# ATSAM3A8C register map
Vendor: Atmel; Series: SAM3A; File version: 0
CPU: CM3 r2p0, selectable endian, MPU, no FPU, 4 interrupt priority bits
Registers are 32-bit, read-write, reset 0x0 unless marked. A register's access mark holds for its fields unless they carry their own. Offsets are from the block's base; [hi:lo] are bit positions; {n}, {i} and the like mark numbered series.

## PMC — Power Management Controller
Base 0x400E0600
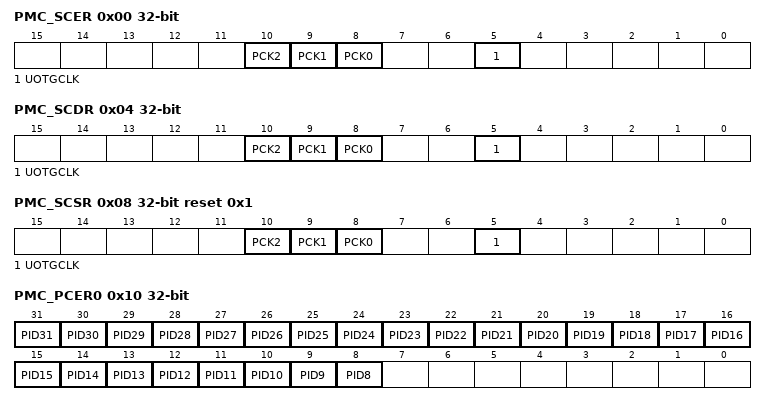
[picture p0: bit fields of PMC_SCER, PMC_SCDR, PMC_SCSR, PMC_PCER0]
0x00 PMC_SCER wo reset not defined — System Clock Enable Register
  [10] PCK2 — Programmable Clock 2 Output Enable
  [9] PCK1 — Programmable Clock 1 Output Enable
  [8] PCK0 — Programmable Clock 0 Output Enable
  [5] UOTGCLK — Enable USB OTG Clock (48 MHz, USB_48M) for UTMI
0x04 PMC_SCDR wo reset not defined — System Clock Disable Register
  [10] PCK2 — Programmable Clock 2 Output Disable
  [9] PCK1 — Programmable Clock 1 Output Disable
  [8] PCK0 — Programmable Clock 0 Output Disable
  [5] UOTGCLK — Disable USB OTG Clock (48 MHz, USB_48M) for UTMI
0x08 PMC_SCSR ro reset 0x1 — System Clock Status Register
  [10] PCK2 — Programmable Clock 2 Output Status
  [9] PCK1 — Programmable Clock 1 Output Status
  [8] PCK0 — Programmable Clock 0 Output Status
  [5] UOTGCLK — USB OTG Clock (48 MHz, USB_48M) Clock Status
0x10 PMC_PCER0 wo reset not defined — Peripheral Clock Enable Register 0
  [n] PID{n} (n=8..31) — Peripheral Clock {n} Enable
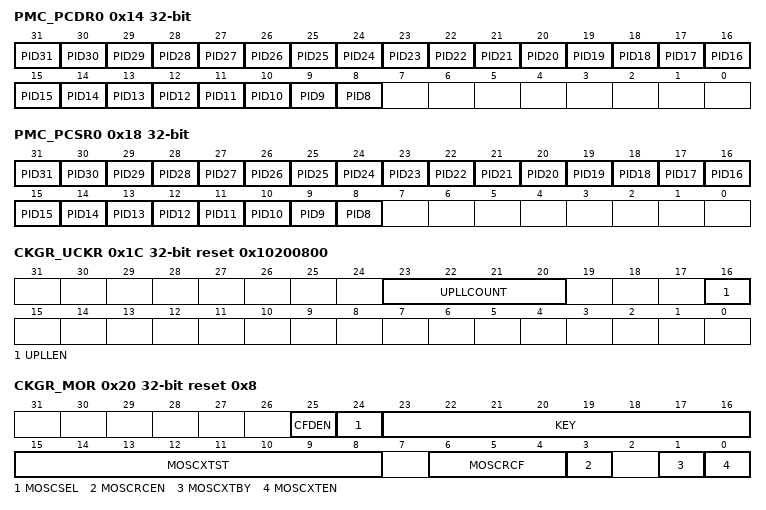
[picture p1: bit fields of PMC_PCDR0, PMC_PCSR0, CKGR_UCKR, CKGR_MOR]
0x14 PMC_PCDR0 wo reset not defined — Peripheral Clock Disable Register 0
  [n] PID{n} (n=8..31) — Peripheral Clock {n} Disable
0x18 PMC_PCSR0 ro — Peripheral Clock Status Register 0
  [n] PID{n} (n=8..31) — Peripheral Clock {n} Status
0x1C CKGR_UCKR reset 0x10200800 — UTMI Clock Register
  [23:20] UPLLCOUNT — UTMI PLL Start-up Time
  [16] UPLLEN — UTMI PLL Enable
0x20 CKGR_MOR reset 0x8 — Main Oscillator Register
  [25] CFDEN — Clock Failure Detector Enable
  [24] MOSCSEL — Main Oscillator Selection
  [23:16] KEY — Write Access Password
    55=PASSWD (Writing any other value in this field aborts the write operation.Always reads as 0.)
  [15:8] MOSCXTST — Main Crystal Oscillator Start-up Time
  [6:4] MOSCRCF — Main On-Chip RC Oscillator Frequency Selection
    0=4_MHz (The Fast RC Oscillator Frequency is at 4 MHz (default)); 1=8_MHz (The Fast RC Oscillator Frequency is at 8 MHz); 2=12_MHz (The Fast RC Oscillator Frequency is at 12 MHz)
  [3] MOSCRCEN — Main On-Chip RC Oscillator Enable
  [1] MOSCXTBY — Main Crystal Oscillator Bypass
  [0] MOSCXTEN — Main Crystal Oscillator Enable
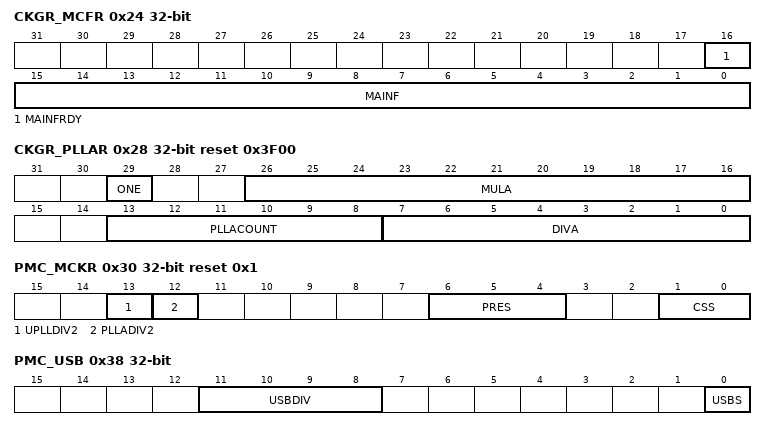
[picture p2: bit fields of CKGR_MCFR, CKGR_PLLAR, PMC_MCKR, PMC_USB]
0x24 CKGR_MCFR ro — Main Clock Frequency Register
  [16] MAINFRDY — Main Clock Ready
  [15:0] MAINF — Main Clock Frequency
0x28 CKGR_PLLAR reset 0x3F00 — PLLA Register
  [29] ONE — Must Be Set to 1
  [26:16] MULA — PLLA Multiplier
  [13:8] PLLACOUNT — PLLA Counter
  [7:0] DIVA — Divider
0x30 PMC_MCKR reset 0x1 — Master Clock Register
  [13] UPLLDIV2
  [12] PLLADIV2 — PLLA Divisor by 2
  [6:4] PRES — Processor Clock Prescaler
    0=CLK_1 (Selected clock); 1=CLK_2 (Selected clock divided by 2); 2=CLK_4 (Selected clock divided by 4); 3=CLK_8 (Selected clock divided by 8); 4=CLK_16 (Selected clock divided by 16); 5=CLK_32 (Selected clock divided by 32); 6=CLK_64 (Selected clock divided by 64); 7=CLK_3 (Selected clock divided by 3)
  [1:0] CSS — Master Clock Source Selection
    0=SLOW_CLK (Slow Clock is selected); 1=MAIN_CLK (Main Clock is selected); 2=PLLA_CLK (PLLA Clock is selected); 3=UPLL_CLK (UPLL Clock is selected)
0x38 PMC_USB — USB Clock Register
  [11:8] USBDIV — Divider for USB Clock.
  [0] USBS — USB Input Clock Selection
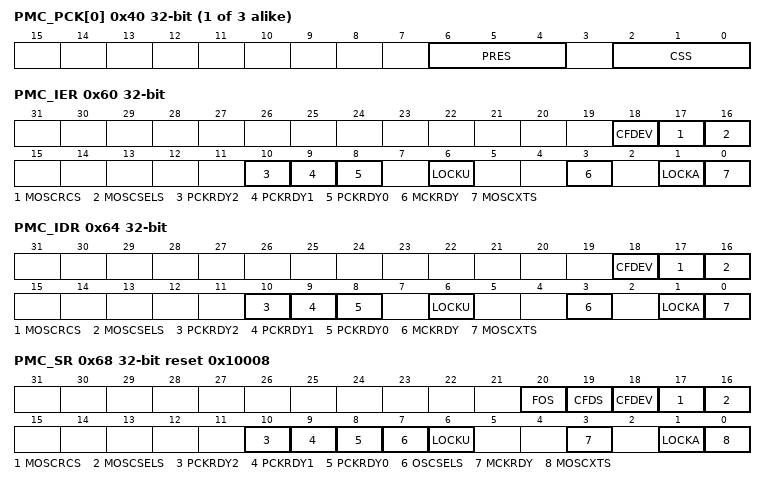
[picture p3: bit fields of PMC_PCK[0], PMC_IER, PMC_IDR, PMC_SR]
{0x40+4i} PMC_PCK[{i}] (i=0..2) reset not defined — Programmable Clock 0 Register
  [6:4] PRES — Programmable Clock Prescaler
    0=CLK_1 (Selected clock); 1=CLK_2 (Selected clock divided by 2); 2=CLK_4 (Selected clock divided by 4); 3=CLK_8 (Selected clock divided by 8); 4=CLK_16 (Selected clock divided by 16); 5=CLK_32 (Selected clock divided by 32); 6=CLK_64 (Selected clock divided by 64)
  [2:0] CSS — Master Clock Source Selection
    0=SLOW_CLK (Slow Clock is selected); 1=MAIN_CLK (Main Clock is selected); 2=PLLA_CLK (PLLA Clock is selected); 3=UPLL_CLK (UPLL Clock is selected); 4=MCK (Master Clock is selected)
0x60 PMC_IER wo reset not defined — Interrupt Enable Register
  [18] CFDEV — Clock Failure Detector Event Interrupt Enable
  [17] MOSCRCS — Main On-Chip RC Status Interrupt Enable
  [16] MOSCSELS — Main Oscillator Selection Status Interrupt Enable
  [10] PCKRDY2 — Programmable Clock Ready 2 Interrupt Enable
  [9] PCKRDY1 — Programmable Clock Ready 1 Interrupt Enable
  [8] PCKRDY0 — Programmable Clock Ready 0 Interrupt Enable
  [6] LOCKU — UTMI PLL Lock Interrupt Enable
  [3] MCKRDY — Master Clock Ready Interrupt Enable
  [1] LOCKA — PLLA Lock Interrupt Enable
  [0] MOSCXTS — Main Crystal Oscillator Status Interrupt Enable
0x64 PMC_IDR wo reset not defined — Interrupt Disable Register
  [18] CFDEV — Clock Failure Detector Event Interrupt Disable
  [17] MOSCRCS — Main On-Chip RC Status Interrupt Disable
  [16] MOSCSELS — Main Oscillator Selection Status Interrupt Disable
  [10] PCKRDY2 — Programmable Clock Ready 2 Interrupt Disable
  [9] PCKRDY1 — Programmable Clock Ready 1 Interrupt Disable
  [8] PCKRDY0 — Programmable Clock Ready 0 Interrupt Disable
  [6] LOCKU — UTMI PLL Lock Interrupt Disable
  [3] MCKRDY — Master Clock Ready Interrupt Disable
  [1] LOCKA — PLLA Lock Interrupt Disable
  [0] MOSCXTS — Main Crystal Oscillator Status Interrupt Disable
0x68 PMC_SR ro reset 0x10008 — Status Register
  [20] FOS — Clock Failure Detector Fault Output Status
  [19] CFDS — Clock Failure Detector Status
  [18] CFDEV — Clock Failure Detector Event
  [17] MOSCRCS — Main On-Chip RC Oscillator Status
  [16] MOSCSELS — Main Oscillator Selection Status
  [10] PCKRDY2 — Programmable Clock Ready Status
  [9] PCKRDY1 — Programmable Clock Ready Status
  [8] PCKRDY0 — Programmable Clock Ready Status
  [7] OSCSELS — Slow Clock Oscillator Selection
  [6] LOCKU — UTMI PLL Lock Status
  [3] MCKRDY — Master Clock Status
  [1] LOCKA — PLLA Lock Status
  [0] MOSCXTS — Main XTAL Oscillator Status
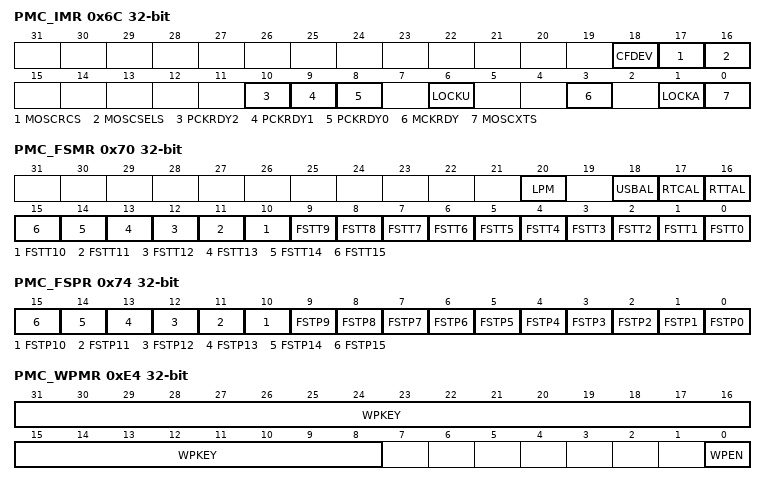
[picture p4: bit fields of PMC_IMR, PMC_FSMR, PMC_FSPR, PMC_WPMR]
0x6C PMC_IMR ro — Interrupt Mask Register
  [18] CFDEV — Clock Failure Detector Event Interrupt Mask
  [17] MOSCRCS — Main On-Chip RC Status Interrupt Mask
  [16] MOSCSELS — Main Oscillator Selection Status Interrupt Mask
  [10] PCKRDY2 — Programmable Clock Ready 2 Interrupt Mask
  [9] PCKRDY1 — Programmable Clock Ready 1 Interrupt Mask
  [8] PCKRDY0 — Programmable Clock Ready 0 Interrupt Mask
  [6] LOCKU — UTMI PLL Lock Interrupt Mask
  [3] MCKRDY — Master Clock Ready Interrupt Mask
  [1] LOCKA — PLLA Lock Interrupt Mask
  [0] MOSCXTS — Main Crystal Oscillator Status Interrupt Mask
0x70 PMC_FSMR — Fast Start-up Mode Register
  [20] LPM — Low Power Mode
  [18] USBAL — USB Alarm Enable
  [17] RTCAL — RTC Alarm Enable
  [16] RTTAL — RTT Alarm Enable
  [n] FSTT{n} (n=0..15) — Fast Start-up Input Enable {n}
0x74 PMC_FSPR — Fast Start-up Polarity Register
  [n] FSTP{n} (n=0..15) — Fast Start-up Input Polarityx
0x78 PMC_FOCR wo reset not defined — Fault Output Clear Register
  [0] FOCLR — Fault Output Clear
0xE4 PMC_WPMR — Write Protect Mode Register
  [31:8] WPKEY — Write Protect KEY
    0x504D43=PASSWD (Writing any other value in this field aborts the write operation of the WPEN bit. Always reads as 0.)
  [0] WPEN — Write Protect Enable
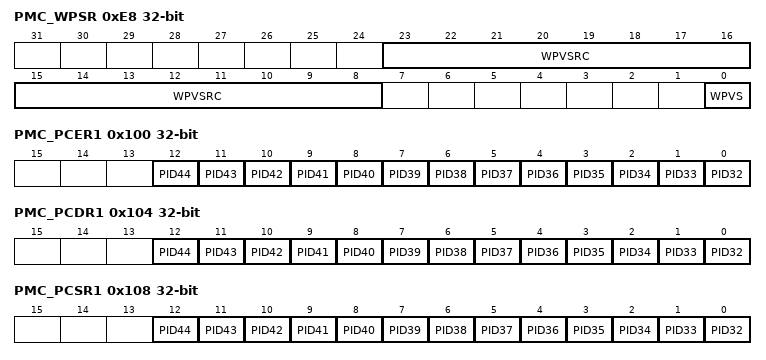
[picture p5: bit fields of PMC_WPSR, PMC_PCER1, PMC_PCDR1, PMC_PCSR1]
0xE8 PMC_WPSR ro — Write Protect Status Register
  [23:8] WPVSRC — Write Protect Violation Source
  [0] WPVS — Write Protect Violation Status
0x100 PMC_PCER1 wo reset not defined — Peripheral Clock Enable Register 1
  [n-32] PID{n} (n=32..44) — Peripheral Clock {n} Enable
0x104 PMC_PCDR1 wo reset not defined — Peripheral Clock Disable Register 1
  [n-32] PID{n} (n=32..44) — Peripheral Clock {n} Disable
0x108 PMC_PCSR1 ro — Peripheral Clock Status Register 1
  [n-32] PID{n} (n=32..44) — Peripheral Clock {n} Status
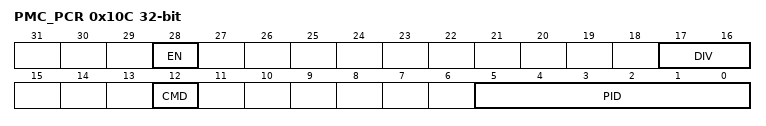
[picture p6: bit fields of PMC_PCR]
0x10C PMC_PCR — Peripheral Control Register
  [28] EN — Enable
  [17:16] DIV — Divisor Value
    0=PERIPH_DIV_MCK (Peripheral clock is MCK); 1=PERIPH_DIV2_MCK (Peripheral clock is MCK/2); 2=PERIPH_DIV4_MCK (Peripheral clock is MCK/4)
  [12] CMD — Command
  [5:0] PID — Peripheral ID

## Notices in the file
SAM Software Package License
Copyright (c) 2015, Atmel Corporation
All rights reserved.
Redistribution and use in source and binary forms, with or without
modification, are permitted provided that the following condition is met:
- Redistributions of source code must retain the above copyright notice,
this list of conditions and the disclaimer below.
Atmel's name may not be used to endorse or promote products derived from
this software without specific prior written permission.
DISCLAIMER:  THIS SOFTWARE IS PROVIDED BY ATMEL "AS IS" AND ANY EXPRESS OR
IMPLIED WARRANTIES, INCLUDING, BUT NOT LIMITED TO, THE IMPLIED WARRANTIES OF
MERCHANTABILITY, FITNESS FOR A PARTICULAR PURPOSE AND NON-INFRINGEMENT ARE
DISCLAIMED. IN NO EVENT SHALL ATMEL BE LIABLE FOR ANY DIRECT, INDIRECT,
INCIDENTAL, SPECIAL, EXEMPLARY, OR CONSEQUENTIAL DAMAGES (INCLUDING, BUT NOT
LIMITED TO, PROCUREMENT OF SUBSTITUTE GOODS OR SERVICES; LOSS OF USE, DATA,
OR PROFITS; OR BUSINESS INTERRUPTION) HOWEVER CAUSED AND ON ANY THEORY OF
LIABILITY, WHETHER IN CONTRACT, STRICT LIABILITY, OR TORT (INCLUDING
NEGLIGENCE OR OTHERWISE) ARISING IN ANY WAY OUT OF THE USE OF THIS SOFTWARE,
EVEN IF ADVISED OF THE POSSIBILITY OF SUCH DAMAGE.
